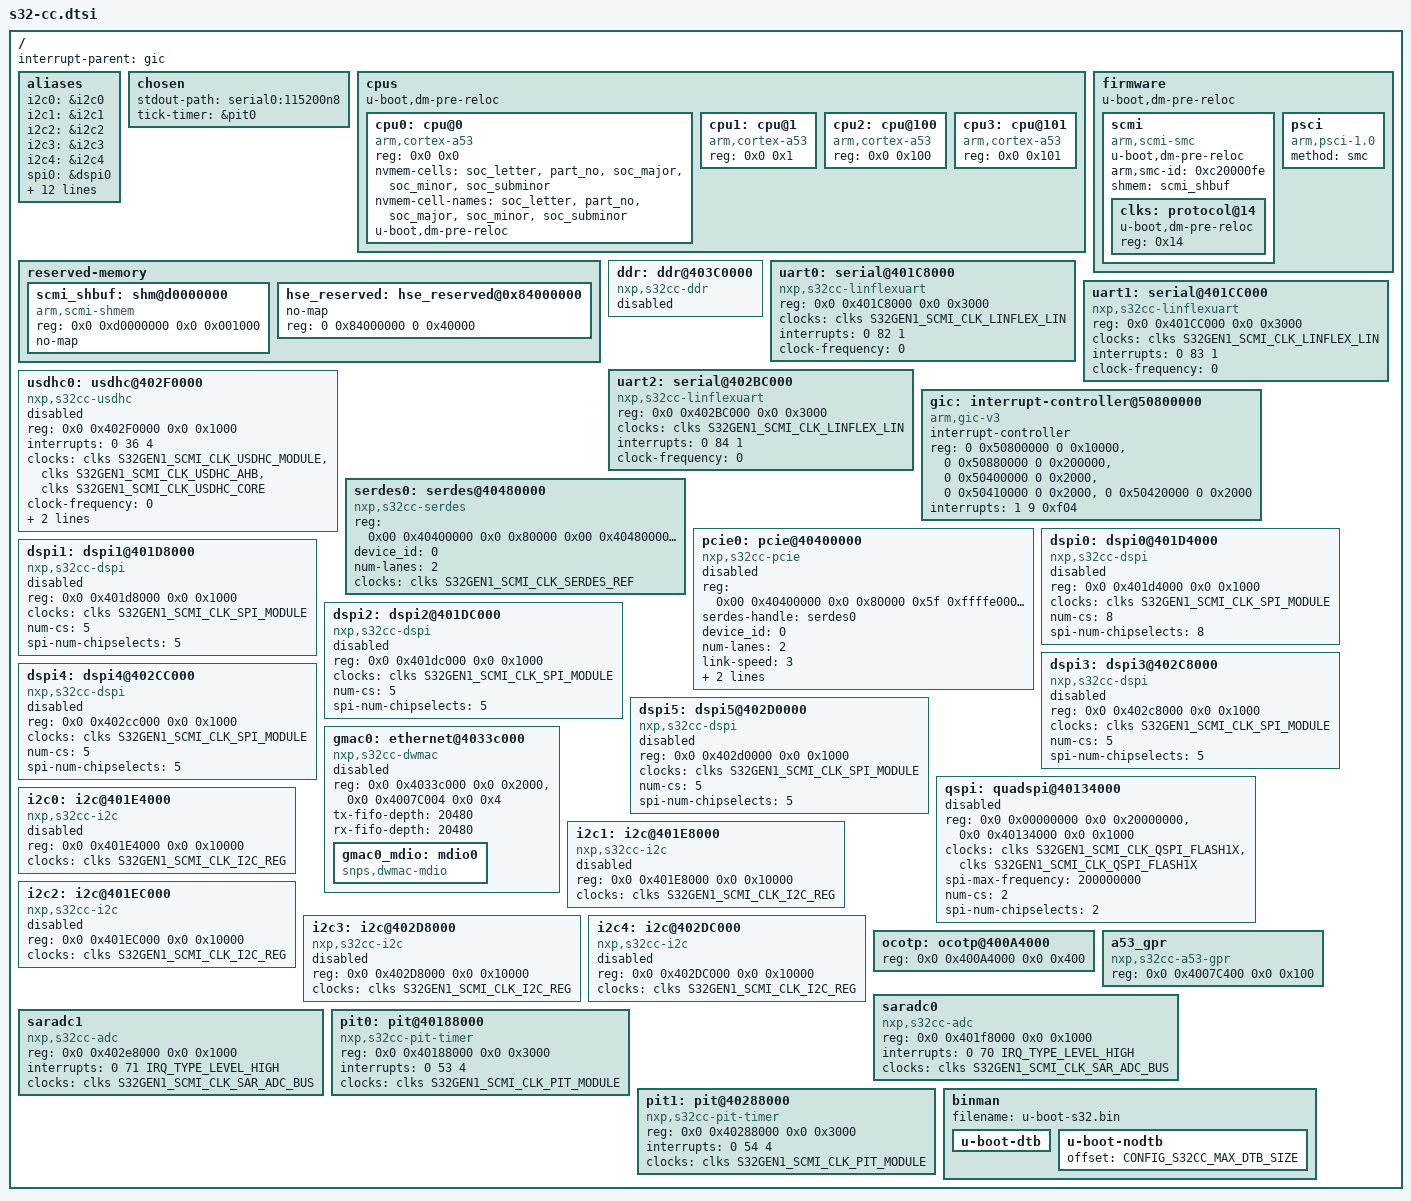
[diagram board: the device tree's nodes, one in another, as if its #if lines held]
// SPDX-License-Identifier: (GPL-2.0+ OR MIT)
/*
 * Device Tree Include file for NXP S32CC family SoCs.
 *
 * Copyright 2019-2022 NXP
 */

#include <dt-bindings/clock/s32gen1-scmi-clock.h>
#include <dt-bindings/interrupt-controller/irq.h>

/ {
	interrupt-parent = <&gic>;
	#address-cells = <2>;
	#size-cells = <2>;

	aliases {
		i2c0 = &i2c0;
		i2c1 = &i2c1;
		i2c2 = &i2c2;
		i2c3 = &i2c3;
		i2c4 = &i2c4;
		spi0 = &dspi0;
		spi1 = &dspi1;
		spi2 = &dspi2;
		spi3 = &dspi3;
		spi4 = &dspi4;
		spi5 = &dspi5;
		spi6 = &qspi;
		serdes0 = &serdes0;
		pcie0 = &pcie0;
		mmc0 = &usdhc0;
		clks = &clks;
		serial0 = &uart0;
		serial1 = &uart1;
	};

	chosen {
		stdout-path = "serial0:115200n8";
		tick-timer = &pit0;
	};

	cpus: cpus {
		#address-cells = <1>;
		#size-cells = <0>;
		u-boot,dm-pre-reloc;

		cpu0: cpu@0 {
			device_type = "cpu";
			compatible = "arm,cortex-a53";
			reg = <0x0 0x0>;

			nvmem-cells = <&soc_letter>, <&part_no>,
			    <&soc_major>, <&soc_minor>, <&soc_subminor>;
			nvmem-cell-names = "soc_letter", "part_no",
			    "soc_major", "soc_minor", "soc_subminor";
			u-boot,dm-pre-reloc;
		};

		cpu1: cpu@1 {
			device_type = "cpu";
			compatible = "arm,cortex-a53";
			reg = <0x0 0x1>;
		};

		cpu2: cpu@100 {
			device_type = "cpu";
			compatible = "arm,cortex-a53";
			reg = <0x0 0x100>;
		};

		cpu3: cpu@101 {
			device_type = "cpu";
			compatible = "arm,cortex-a53";
			reg = <0x0 0x101>;
		};
	};

	reserved-memory {
		#address-cells = <2>;
		#size-cells = <2>;
		ranges;

		scmi_shbuf: shm@d0000000 {
			compatible = "arm,scmi-shmem";
			reg = <0x0 0xd0000000 0x0 0x001000>;
			no-map;
		};

#ifdef CONFIG_HSE_SECBOOT
		hse_reserved: hse_reserved@0x84000000 {
			no-map;
			reg = <0 0x84000000 0 0x40000>; /* 256K */
		};
#endif
	};

	firmware {
		u-boot,dm-pre-reloc;

		scmi {
			u-boot,dm-pre-reloc;
			compatible = "arm,scmi-smc";
			arm,smc-id = <0xc20000fe>;
			shmem = <&scmi_shbuf>;
			#address-cells = <1>;
			#size-cells = <0>;

			status = "okay";

			clks: protocol@14 {
				u-boot,dm-pre-reloc;
				#address-cells = <2>;
				#size-cells = <2>;

				reg = <0x14>;
				#clock-cells = <1>;
			};
		};

		psci {
			compatible = "arm,psci-1.0";
			method = "smc";
		};
	};

	ddr: ddr@403C0000 {
		compatible = "nxp,s32cc-ddr";
		/* Will be modified by ATF */
		status = "disabled";
	};

	uart0:serial@401C8000 {
		device_type = "serial";
		compatible = "nxp,s32cc-linflexuart";
		reg = <0x0 0x401C8000 0x0 0x3000>;
		clocks = <&clks S32GEN1_SCMI_CLK_LINFLEX_LIN>;
		clock-names = "lin";
		interrupts = <0 82 1>;
		clock-frequency = <0>;	/* updated dynamically if 0 */
	};

	uart1:serial@401CC000 {
		device_type = "serial";
		compatible = "nxp,s32cc-linflexuart";
		reg = <0x0 0x401CC000 0x0 0x3000>;
		clocks = <&clks S32GEN1_SCMI_CLK_LINFLEX_LIN>;
		clock-names = "lin";
		interrupts = <0 83 1>;
		clock-frequency = <0>;	/* updated dynamically if 0 */
	};

	uart2:serial@402BC000 {
		device_type = "serial";
		compatible = "nxp,s32cc-linflexuart";
		reg = <0x0 0x402BC000 0x0 0x3000>;
		clocks = <&clks S32GEN1_SCMI_CLK_LINFLEX_LIN>;
		clock-names = "lin";
		interrupts = <0 84 1>;
		clock-frequency = <0>;	/* updated dynamically if 0 */
	};

	usdhc0: usdhc@402F0000{
		compatible = "nxp,s32cc-usdhc";
		reg = <0x0 0x402F0000 0x0 0x1000>;
		interrupts = <0 36 4>;
		clocks = <&clks S32GEN1_SCMI_CLK_USDHC_MODULE>,
			<&clks S32GEN1_SCMI_CLK_USDHC_AHB>,
			<&clks S32GEN1_SCMI_CLK_USDHC_CORE>;
		clock-names = "ipg", "ahb", "per";
		clock-frequency = <0>;	/* updated dynamically if 0 */
		bus-width = <8>;
		/* The property name is misleading. Actually means DDR52 is
		 * supported at both 1.8V and 3.3V
		 */
		mmc-ddr-1_8v;
		status = "disabled";
	};

	gic: interrupt-controller@50800000 {
		compatible = "arm,gic-v3";
		#interrupt-cells = <3>;
		#address-cells = <2>;
		#size-cells = <2>;
		interrupt-controller;
		reg = <0 0x50800000 0 0x10000>, /* GIC Dist */
		      <0 0x50880000 0 0x200000>, /* GICR (RD_base + SGI_base) */
		      <0 0x50400000 0 0x2000>, /* GICC */
		      <0 0x50410000 0 0x2000>, /* GICH */
		      <0 0x50420000 0 0x2000>; /* GICV */
		interrupts = <1 9 0xf04>;
	};

	serdes0: serdes@40480000 {
		compatible = "nxp,s32cc-serdes";
		reg = <0x00 0x40400000 0x0 0x80000   /* dbi registers */
		       0x00 0x40480000 0x0 0x04000>; /* serdes registers */
		reg-names = "dbi", "ss";
		#address-cells = <3>;
		#size-cells = <2>;
		device_type = "pci-generic";
		device_id = <0>;
		num-lanes = <2>; /* supports max 2 lanes */
		clocks = <&clks S32GEN1_SCMI_CLK_SERDES_REF>;
	};

	pcie0: pcie@40400000 {
		compatible = "nxp,s32cc-pcie";
		reg =
			<0x00 0x40400000 0x0 0x80000   /* dbi registers */
			/* configuration space, 4KB each for cfg0 and cfg1
			 * at the end of the outbound memory map
			 */
			0x5f 0xffffe000 0x0 0x00002000>;
		reg-names = "dbi", "config";
		#address-cells = <3>;
		#size-cells = <2>;
		device_type = "pci";
		serdes-handle = <&serdes0>;
		device_id = <0>;
		num-lanes = <2>; /* supports max 2 lanes */
		link-speed = <3>; /* supports Gen3 speed */
		nvmem-cells = <&siul2_0_nvram>;

		bus-range = <0x0 0xff>;
		ranges =
			/* downstream I/O, 64KB and aligned naturally just before
			 * the config space to minimize fragmentation
			 */
			<0x81000000 0x0 0x00000000 0x5f 0xfffe0000 0x0 0x00010000
			/* non-prefetchable memory, with best case size
			 * and alignment
			 */
			 0x82000000 0x0 0x00000000 0x58 0x00000000 0x7 0xfffe0000>;
		status = "disabled";
	};

	dspi0: dspi0@401D4000 {
		#address-cells = <1>;
		#size-cells = <0>;
		compatible = "nxp,s32cc-dspi";
		reg = <0x0 0x401d4000 0x0 0x1000>;
		clocks = <&clks S32GEN1_SCMI_CLK_SPI_MODULE>;
		clock-names = "dspi";
		// For U-Boot 2020.04 only
		num-cs = <8>;
		spi-num-chipselects = <8>;
		status = "disabled";
	};

	dspi1: dspi1@401D8000 {
		#address-cells = <1>;
		#size-cells = <0>;
		compatible = "nxp,s32cc-dspi";
		reg = <0x0 0x401d8000 0x0 0x1000>;
		clocks = <&clks S32GEN1_SCMI_CLK_SPI_MODULE>;
		clock-names = "dspi";
		// For U-Boot 2020.04 only
		num-cs = <5>;
		spi-num-chipselects = <5>;
		status = "disabled";
	};

	dspi2: dspi2@401DC000 {
		#address-cells = <1>;
		#size-cells = <0>;
		compatible = "nxp,s32cc-dspi";
		reg = <0x0 0x401dc000 0x0 0x1000>;
		clocks = <&clks S32GEN1_SCMI_CLK_SPI_MODULE>;
		clock-names = "dspi";
		// For U-Boot 2020.04 only
		num-cs = <5>;
		spi-num-chipselects = <5>;
		status = "disabled";
	};

	dspi3: dspi3@402C8000 {
		#address-cells = <1>;
		#size-cells = <0>;
		compatible = "nxp,s32cc-dspi";
		reg = <0x0 0x402c8000 0x0 0x1000>;
		clocks = <&clks S32GEN1_SCMI_CLK_SPI_MODULE>;
		clock-names = "dspi";
		// For U-Boot 2020.04 only
		num-cs = <5>;
		spi-num-chipselects = <5>;
		status = "disabled";
	};

	dspi4: dspi4@402CC000 {
		#address-cells = <1>;
		#size-cells = <0>;
		compatible = "nxp,s32cc-dspi";
		reg = <0x0 0x402cc000 0x0 0x1000>;
		clocks = <&clks S32GEN1_SCMI_CLK_SPI_MODULE>;
		clock-names = "dspi";
		// For U-Boot 2020.04 only
		num-cs = <5>;
		spi-num-chipselects = <5>;
		status = "disabled";
	};

	dspi5: dspi5@402D0000 {
		#address-cells = <1>;
		#size-cells = <0>;
		compatible = "nxp,s32cc-dspi";
		reg = <0x0 0x402d0000 0x0 0x1000>;
		clocks = <&clks S32GEN1_SCMI_CLK_SPI_MODULE>;
		clock-names = "dspi";
		// For U-Boot 2020.04 only
		num-cs = <5>;
		spi-num-chipselects = <5>;
		status = "disabled";
	};

	qspi: quadspi@40134000 {
		#address-cells = <1>;
		#size-cells = <0>;
		reg = <0x0 0x00000000 0x0 0x20000000>,
			<0x0 0x40134000 0x0 0x1000>;
		reg-names = "QuadSPI-memory", "QuadSPI";
		clock-names = "qspi_en", "qspi";
		clocks = <&clks S32GEN1_SCMI_CLK_QSPI_FLASH1X>,
			 <&clks S32GEN1_SCMI_CLK_QSPI_FLASH1X>;
		spi-max-frequency = <200000000>;
		// For U-Boot 2020.04 only
		num-cs = <2>;
		spi-num-chipselects = <2>;
		status = "disabled";
	};

	gmac0: ethernet@4033c000 {
		compatible = "nxp,s32cc-dwmac";
		reg = <0x0 0x4033c000 0x0 0x2000>, /* gmac IP */
		      <0x0 0x4007C004 0x0 0x4>;    /* S32 CTRL_STS reg */
		tx-fifo-depth = <20480>;
		rx-fifo-depth = <20480>;
		status = "disabled";
		gmac0_mdio: mdio0 {
			compatible = "snps,dwmac-mdio";
		};
	};

	i2c0: i2c@401E4000 {
		compatible = "nxp,s32cc-i2c";
		#address-cells = <1>;
		#size-cells = <0>;
		reg = <0x0 0x401E4000 0x0 0x10000>;
		clocks = <&clks S32GEN1_SCMI_CLK_I2C_REG>;
		status = "disabled";
	};

	i2c1: i2c@401E8000 {
		compatible = "nxp,s32cc-i2c";
		#address-cells = <1>;
		#size-cells = <0>;
		reg = <0x0 0x401E8000 0x0 0x10000>;
		clocks = <&clks S32GEN1_SCMI_CLK_I2C_REG>;
		status = "disabled";
	};

	i2c2: i2c@401EC000 {
		compatible = "nxp,s32cc-i2c";
		#address-cells = <1>;
		#size-cells = <0>;
		reg = <0x0 0x401EC000 0x0 0x10000>;
		clocks = <&clks S32GEN1_SCMI_CLK_I2C_REG>;
		status = "disabled";
	};

	i2c3: i2c@402D8000 {
		compatible = "nxp,s32cc-i2c";
		#address-cells = <1>;
		#size-cells = <0>;
		reg = <0x0 0x402D8000 0x0 0x10000>;
		clocks = <&clks S32GEN1_SCMI_CLK_I2C_REG>;
		status = "disabled";
	};

	i2c4: i2c@402DC000 {
		compatible = "nxp,s32cc-i2c";
		#address-cells = <1>;
		#size-cells = <0>;
		reg = <0x0 0x402DC000 0x0 0x10000>;
		clocks = <&clks S32GEN1_SCMI_CLK_I2C_REG>;
		status = "disabled";
	};

	ocotp: ocotp@400A4000 {
		reg = <0x0 0x400A4000 0x0 0x400>;
		status = "okay";
	};

	a53_gpr {
		compatible = "nxp,s32cc-a53-gpr";
		reg = <0x0 0x4007C400 0x0 0x100>;
		status = "okay";
	};

	saradc0: saradc0 {
		compatible = "nxp,s32cc-adc";
		reg = <0x0 0x401f8000 0x0 0x1000>;
		interrupts = <0 70 IRQ_TYPE_LEVEL_HIGH>;
		clocks = <&clks S32GEN1_SCMI_CLK_SAR_ADC_BUS>;
		clock-names = "adc";
		status = "okay";
	};

	saradc1: saradc1 {
		compatible = "nxp,s32cc-adc";
		reg = <0x0 0x402e8000 0x0 0x1000>;
		interrupts = <0 71 IRQ_TYPE_LEVEL_HIGH>;
		clocks = <&clks S32GEN1_SCMI_CLK_SAR_ADC_BUS>;
		clock-names = "adc";
		status = "okay";
	};

	pit0: pit@40188000 {
		compatible = "nxp,s32cc-pit-timer";
		reg = <0x0 0x40188000 0x0 0x3000>;
		interrupts = <0 53 4>;
		clocks = <&clks S32GEN1_SCMI_CLK_PIT_MODULE>;
		clock-names = "pit";
		status = "okay";
	};

	pit1: pit@40288000 {
		compatible = "nxp,s32cc-pit-timer";
		reg = <0x0 0x40288000 0x0 0x3000>;
		interrupts = <0 54 4>;
		clocks = <&clks S32GEN1_SCMI_CLK_PIT_MODULE>;
		clock-names = "pit";
		status = "okay";
	};

	binman {
		filename = "u-boot-s32.bin";
		u-boot-dtb {
		};
		u-boot-nodtb {
			offset = <CONFIG_S32CC_MAX_DTB_SIZE>;
		};
	};

};

